# D1H register map
Vendor: Allwinner; File version: 1.0
Registers are 32-bit, read-write, reset 0x0 unless marked. A register's access mark holds for its fields unless they carry their own. Offsets are from the block's base; [hi:lo] are bit positions; {n}, {i} and the like mark numbered series.

## GPADC — General Purpose ADC
Base 0x02009000
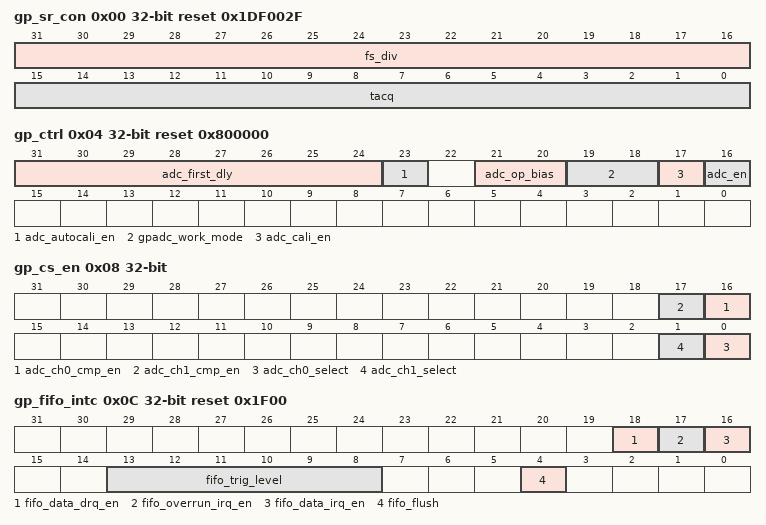
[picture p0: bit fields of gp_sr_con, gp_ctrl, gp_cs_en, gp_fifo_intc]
0x00 gp_sr_con reset 0x1DF002F — GPADC Sample Rate Configure Register
  [31:16] fs_div — ADC sample frequency divider . CLK_IN/(n+1) . Default value: 50K
  [15:0] tacq — ADC acquire time (n+1)/CLK_IN . Default value: 2 us
0x04 gp_ctrl reset 0x800000 (reset mask 0xBF0000) — GPADC Control Register
  [31:24] adc_first_dly — ADC First Convert Delay Setting . ADC conversion of each channel is delayed by N samples
  [23] adc_autocali_en — ADC Auto Calibration
  [21:20] adc_op_bias — ADC OP Bias . Adjust the bandwidth of the ADC amplifier
  [19:18] gpadc_work_mode
    0=SINGLE (Single conversion mode); 2=CONTINUOUS (Continuous conversion mode); 3=BURST (Burst conversion mode)
  [17] adc_cali_en — ADC Calibration
    1=START (Start Calibration, it is cleared to 0 after calibration)
  [16] adc_en — ADC Function Enable . Before the bit is enabled, configure ADC parameters including the work mode and channel number, etc.
    0=DISABLE; 1=ENABLE
0x08 gp_cs_en (reset mask 0x30003) — GPADC Compare and Select Enable Register
  [n+16] adc_ch{n}_cmp_en (n=0..1) — Channel Compare Enable
    0=DISABLE; 1=ENABLE
  [n] adc_ch{n}_select (n=0..1) — Analog Input Channel Select
    0=DISABLE; 1=ENABLE
0x0C gp_fifo_intc reset 0x1F00 — GPADC FIFO Interrupt Control Register
  [18] fifo_data_drq_en — ADC FIFO Date DRQ Enable
    0=DISABLE; 1=ENABLE
  [17] fifo_overrun_irq_en — ADC FIFO Overrun IRQ Enable
    0=DISABLE; 1=ENABLE
  [16] fifo_data_irq_en — ADC FIFO Data Available IRQ Enable
    0=DISABLE; 1=ENABLE
  [13:8] fifo_trig_level — Interrupt trigger level for ADC . Trigger Level = TXTL + 1
  [4] fifo_flush — ADC FIFO Flush . Write 1 to flush TX FIFO, clear automatically to 0.
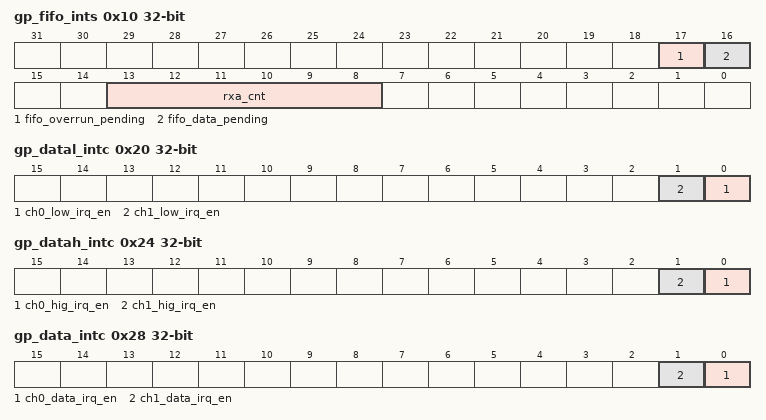
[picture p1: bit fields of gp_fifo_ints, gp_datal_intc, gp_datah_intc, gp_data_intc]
0x10 gp_fifo_ints — GPADC FIFO Interrupt Status Register
  [17] fifo_overrun_pending write-1-clears — ADC FIFO Overrun IRQ Pending
    0=NP_PENDING (No Pending IRQ); 1=PENDING (FIFO Overrun Pending IRQ)
  [16] fifo_data_pending write-1-clears — ADC FIFO Data Available Pending Bit
    0=NO_PENDING (NO Pending IRQ); 1=PENDING (FIFO Available Pending IRQ)
  [13:8] rxa_cnt ro — ADC FIFO available sample word counter
0x14 gp_fifo_data — GPADC FIFO Data Register
  [11:0] gp_fifo_data ro — GPADC Data in FIFO
0x18 gp_cdata — GPADC Calibration Data Register
  [11:0] gp_cdata — GPADC Calibration Data
0x20 gp_datal_intc (reset mask 0x3) — GPADC Data Low Interrupt Configure Register
  [n] ch{n}_low_irq_en (n=0..1) — Channel Voltage Low Available Interrupt Enable
    0=DISABLE; 1=ENABLE
0x24 gp_datah_intc (reset mask 0x3) — GPADC Data High Interrupt Configure Register
  [n] ch{n}_hig_irq_en (n=0..1) — Channel Voltage High Available Interrupt Enable
    0=DISABLE; 1=ENABLE
0x28 gp_data_intc (reset mask 0x3) — GPADC Data Interrupt Configure Register
  [n] ch{n}_data_irq_en (n=0..1) — Channel Data Interrupt Enable
    0=DISABLE; 1=ENABLE
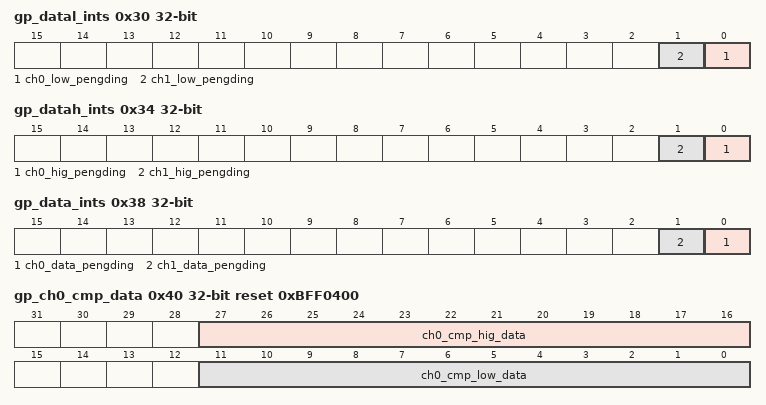
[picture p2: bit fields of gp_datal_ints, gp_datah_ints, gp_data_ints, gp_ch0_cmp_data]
0x30 gp_datal_ints (reset mask 0x3) — GPADC Data Low Interrupt Status Register
  [n] ch{n}_low_pengding (n=0..1) write-1-clears — Channel Voltage Low Available Interrupt Status
    0=NO_PENDING (NO Pending IRQ); 1=PENDING (Channel Voltage Low Available Pending IRQ)
0x34 gp_datah_ints (reset mask 0x3) — GPADC Data High Interrupt Status Register
  [n] ch{n}_hig_pengding (n=0..1) write-1-clears — Channel Voltage High Available Interrupt Status
    0=NO_PENDING (No Pending IRQ); 1=CHANNEL (Channel Voltage High Available Pending IRQ)
0x38 gp_data_ints (reset mask 0x3) — GPADC Data Interrupt Status Register
  [n] ch{n}_data_pengding (n=0..1) write-1-clears — Channel Data Available Interrupt Status
    0=NO_PENDING (No Pending IRQ); 1=CHANNEL (Channel Data Available Pending IRQ)
0x40 gp_ch0_cmp_data reset 0xBFF0400 — GPADC CH0 Compare Data Register
  [27:16] ch0_cmp_hig_data — Channel 0 Voltage High Value
  [11:0] ch0_cmp_low_data — Channel 0 Voltage Low Value
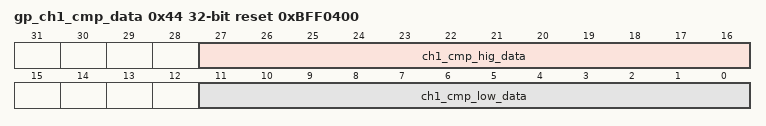
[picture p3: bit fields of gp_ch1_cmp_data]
0x44 gp_ch1_cmp_data reset 0xBFF0400 — GPADC CH1 Compare Data Register
  [27:16] ch1_cmp_hig_data — Channel 1 Voltage High Value
  [11:0] ch1_cmp_low_data — Channel 1 Voltage Low Value
0x80 gp_ch0_data — GPADC CH0 Data Register
  [11:0] gp_ch0_data ro — Channel 0 Data
0x84 gp_ch1_data — GPADC CH1 Data Register
  [11:0] gp_ch1_data ro — Channel 1 Data
